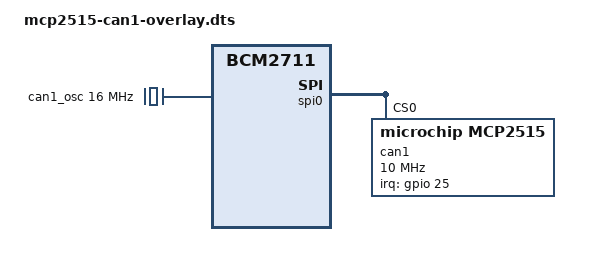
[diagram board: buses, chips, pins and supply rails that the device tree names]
/*
 * Device tree overlay for mcp251x/can1 on spi0.1 edited by petit_miner
 */

/dts-v1/;
/plugin/;

/ {
    compatible = "brcm,bcm2711";
    /* disable spi-dev for spi0.1 */
    fragment@0 {
        target = <&spi0>;
        __overlay__ {
            status = "okay";
        };
    };

    fragment@1 {
	target = <&spidev1>;
	__overlay__ {
	    status = "disabled";
	};
    };

    /* the interrupt pin of the can-controller */
    fragment@2 {
        target = <&gpio>;
        __overlay__ {
            can1_pins: can1_pins {
                brcm,pins = <24>; /* default pin, it will be overriden */
                brcm,function = <0>; /* input */
            };
        };
    };

    /* the clock/oscillator of the can-controller */
    fragment@3 {
        target-path = "/";
        __overlay__ {
            /* external oscillator of mcp2515 on spi0.1 */
            can1_osc: can1_osc {
                compatible = "fixed-clock";
                #clock-cells = <0>;
                clock-frequency  = <16000000>; /* default ext clock speed, it will be overriden */
            };
        };
    };

    /* the spi config of the can-controller itself binding everything together */
    fragment@4 {
        target = <&spi0>;
        __overlay__ {
            /* needed to avoid dtc warning */
            #address-cells = <1>;
            #size-cells = <0>;
            can1: mcp2515@0 {	/* don't know why must be zero for spi0.1 */
                reg = <0>;	/* " */
                compatible = "microchip,mcp2515";
                pinctrl-names = "default";
                pinctrl-0 = <&can1_pins>;
                spi-max-frequency = <10000000>;
                interrupt-parent = <&gpio>;
                interrupts = <25 8>; /* IRQ_TYPE_LEVEL_LOW */
                clocks = <&can1_osc>;
            };
        };
    };
    __overrides__ {
        oscillator = <&can1_osc>,"clock-frequency:0";
        spimaxfrequency = <&can1>,"spi-max-frequency:0";
        interrupt = <&can1_pins>,"brcm,pins:0",<&can1>,"interrupts:0";
    };
};
